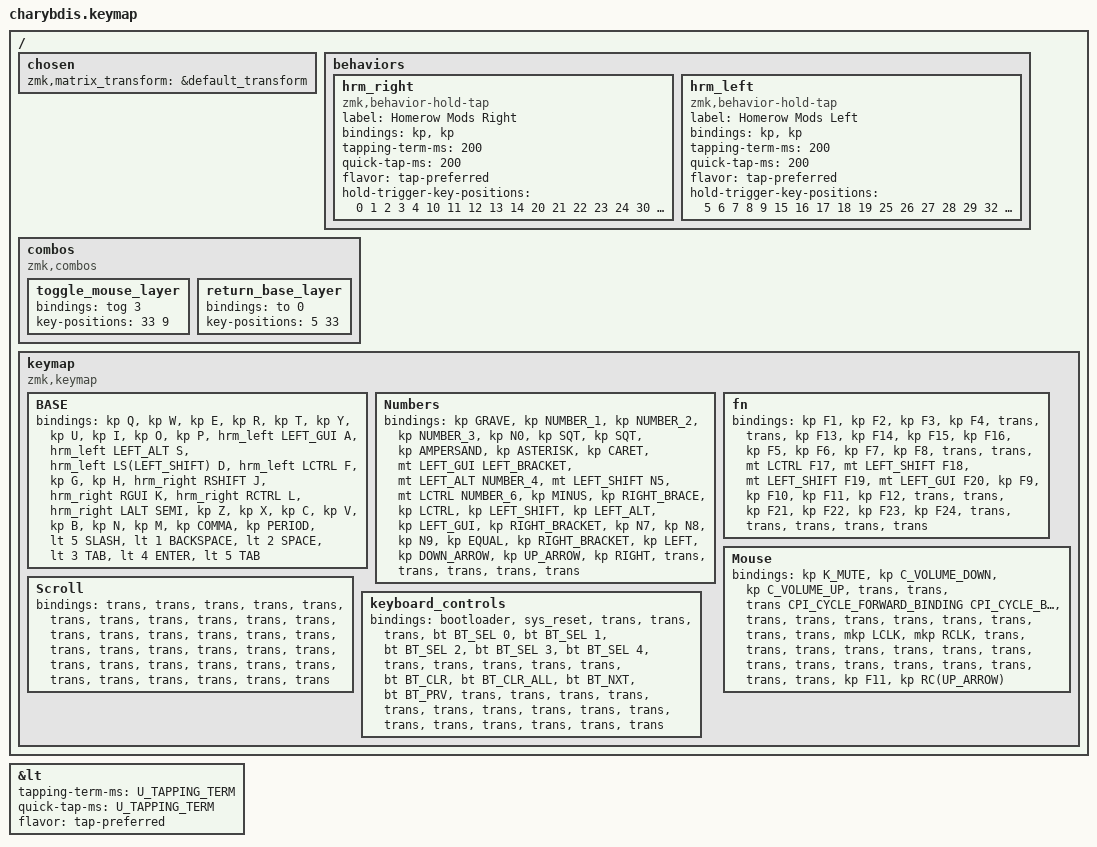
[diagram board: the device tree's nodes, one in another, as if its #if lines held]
#include <behaviors/mouse_keys.dtsi>
#include <dt-bindings/zmk/mouse.h>
#include <behaviors.dtsi>
#include <dt-bindings/zmk/bt.h>
#include <dt-bindings/zmk/keys.h>
#include <dt-bindings/zmk/pointing.h>

#define U_TAPPING_TERM 200

#if defined(CONFIG_SHIELD_CHARYBDIS_RIGHT)

#define CPI_CYCLE_FORWARD_BINDING &cpi_cycle 1
#define CPI_CYCLE_BACKWARD_BINDING &cpi_cycle 3

#else

#define CPI_CYCLE_FORWARD_BINDING &none
#define CPI_CYCLE_BACKWARD_BINDING &none

#endif

&lt {
    tapping-term-ms = < U_TAPPING_TERM >;
    quick-tap-ms = < U_TAPPING_TERM >;
    flavor = "tap-preferred";
};

/ {
    chosen { zmk,matrix_transform = &default_transform; };
};

/ {
    behaviors {
        hrm_right: hrm_right {
            compatible = "zmk,behavior-hold-tap";
            label = "Homerow Mods Right";
            bindings = <&kp>, <&kp>;

            #binding-cells = <2>;
            tapping-term-ms = <200>;
            quick-tap-ms = <200>;
            flavor = "tap-preferred";
            hold-trigger-key-positions = <0 1 2 3 4 10 11 12 13 14 20 21 22 23 24 30 31>;
        };

        hrm_left: hrm_left {
            compatible = "zmk,behavior-hold-tap";
            label = "Homerow Mods Left";
            bindings = <&kp>, <&kp>;

            #binding-cells = <2>;
            tapping-term-ms = <200>;
            quick-tap-ms = <200>;
            flavor = "tap-preferred";
            hold-trigger-key-positions = <5 6 7 8 9 15 16 17 18 19 25 26 27 28 29 32 33>;
        };
    };

    combos {
        compatible = "zmk,combos";

        toggle_mouse_layer {
            bindings = <&tog 3>;
            key-positions = <33 9>;
        };

        return_base_layer {
            bindings = <&to 0>;
            key-positions = <5 33>;
        };
    };

    keymap {
        compatible = "zmk,keymap";

        BASE {
            bindings = <
&kp Q                 &kp W                 &kp E                       &kp R              &kp T                   &kp Y  &kp U                &kp I              &kp O               &kp P
&hrm_left LEFT_GUI A  &hrm_left LEFT_ALT S  &hrm_left LS(LEFT_SHIFT) D  &hrm_left LCTRL F  &kp G                   &kp H  &hrm_right RSHIFT J  &hrm_right RGUI K  &hrm_right RCTRL L  &hrm_right LALT SEMI
&kp Z                 &kp X                 &kp C                       &kp V              &kp B                   &kp N  &kp M                &kp COMMA          &kp PERIOD          &lt 5 SLASH
                                                                        &lt 1 BACKSPACE    &lt 2 SPACE  &lt 3 TAB         &lt 4 ENTER          &lt 5 TAB
            >;
        };

        Numbers {
            bindings = <
&kp GRAVE                  &kp NUMBER_1           &kp NUMBER_2       &kp NUMBER_3        &kp N0             &kp SQT            &kp SQT    &kp AMPERSAND   &kp ASTERISK  &kp CARET
&mt LEFT_GUI LEFT_BRACKET  &mt LEFT_ALT NUMBER_4  &mt LEFT_SHIFT N5  &mt LCTRL NUMBER_6  &kp MINUS          &kp RIGHT_BRACE    &kp LCTRL  &kp LEFT_SHIFT  &kp LEFT_ALT  &kp LEFT_GUI
&kp RIGHT_BRACKET          &kp N7                 &kp N8             &kp N9              &kp EQUAL          &kp RIGHT_BRACKET  &kp LEFT   &kp DOWN_ARROW  &kp UP_ARROW  &kp RIGHT
                                                                     &trans              &trans     &trans                     &trans     &trans
            >;
        };

        fn {
            bindings = <
&kp F1  &kp F2   &kp F3   &kp F4   &trans          &trans  &kp F13        &kp F14             &kp F15             &kp F16
&kp F5  &kp F6   &kp F7   &kp F8   &trans          &trans  &mt LCTRL F17  &mt LEFT_SHIFT F18  &mt LEFT_SHIFT F19  &mt LEFT_GUI F20
&kp F9  &kp F10  &kp F11  &kp F12  &trans          &trans  &kp F21        &kp F22             &kp F23             &kp F24
                          &trans   &trans  &trans          &trans         &trans
            >;
        };

        Mouse {
            bindings = <
&kp K_MUTE  &kp C_VOLUME_DOWN  &kp C_VOLUME_UP  &trans  &trans                       &trans CPI_CYCLE_FORWARD_BINDING CPI_CYCLE_BACKWARD_BINDING  &trans  &trans  &trans  &trans
&trans      &trans             &trans           &trans  &mkp LCLK                    &mkp RCLK                                                    &trans  &trans  &trans  &trans
&trans      &trans             &trans           &trans  &trans                       &trans                                                       &trans  &trans  &trans  &trans
                                                &trans  &kp F11    &kp RC(UP_ARROW)
            >;
        };

        Scroll {
            bindings = <
&trans  &trans  &trans  &trans  &trans          &trans  &trans  &trans  &trans  &trans
&trans  &trans  &trans  &trans  &trans          &trans  &trans  &trans  &trans  &trans
&trans  &trans  &trans  &trans  &trans          &trans  &trans  &trans  &trans  &trans
                        &trans  &trans  &trans          &trans  &trans
            >;
        };

        keyboard_controls {
            bindings = <
&bootloader  &sys_reset  &trans  &trans  &trans          &bt BT_SEL 0  &bt BT_SEL 1    &bt BT_SEL 2  &bt BT_SEL 3  &bt BT_SEL 4
&trans       &trans      &trans  &trans  &trans          &bt BT_CLR    &bt BT_CLR_ALL  &bt BT_NXT    &bt BT_PRV    &trans
&trans       &trans      &trans  &trans  &trans          &trans        &trans          &trans        &trans        &trans
                                 &trans  &trans  &trans                &trans          &trans
            >;
        };
    };
};
